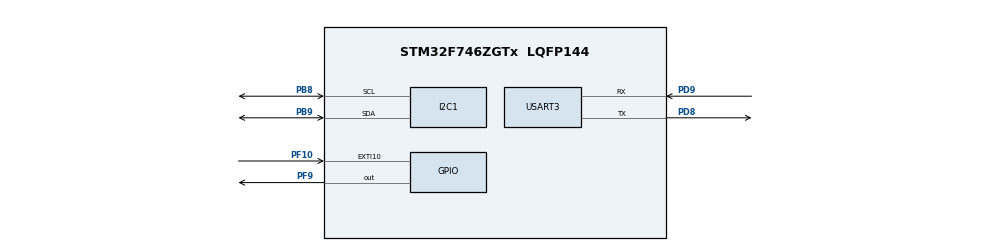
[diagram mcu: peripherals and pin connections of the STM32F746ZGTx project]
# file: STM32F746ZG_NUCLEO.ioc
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Mcu.Family=STM32F7
Mcu.Name=STM32F746ZGTx
Mcu.Package=LQFP144
NVIC.PriorityGroup=NVIC_PRIORITYGROUP_4
PB8.Mode=I2C
PB8.Signal=I2C1_SCL
PB9.Mode=I2C
PB9.Signal=I2C1_SDA
PD8.Mode=Asynchronous
PD8.Signal=USART3_TX
PD9.Mode=Asynchronous
PD9.Signal=USART3_RX
PF10.Signal=GPXTI10
PF9.Signal=GPIO_Output
ProjectManager.HeapSize=0x200
ProjectManager.StackSize=0x400
ProjectManager.TargetToolchain=EWARM V8.32
RCC.HSE_VALUE=25000000
RCC.HSI_VALUE=16000000
RCC.LSE_VALUE=32768
RCC.USBFreq_Value=96000000
RCC.VCOOutputFreq_Value=192000000
STMicroelectronics.I-CUBE-STDIO.1.4.0.STDIN_UART_HANDLER=huart3
STMicroelectronics.I-CUBE-STDIO.1.4.0.STDIOCcCompilerJjIOoOJjSTDIN=USART
STMicroelectronics.I-CUBE-STDIO.1.4.0.STDIOCcCompilerJjIOoOJjSTDOUT=LCD
STMicroelectronics.X-CUBE-COMPONENTS.1.2.3.LCDCcComponentsJjLCDControllerJjGrove=I2C
USART3.VirtualMode-Asynchronous=VM_ASYNC
VP_STMicroelectronics.I-CUBE-STDIO_VS_CompilerJjSTDIO_1.0.0.Mode=CompilerJjSTDIO
VP_STMicroelectronics.X-CUBE-COMPONENTS_VS_ComponentsJjLCD_1.0.0.Mode=ComponentsJjLCD
board=custom

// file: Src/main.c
/* USER CODE BEGIN Header */
/**
  ******************************************************************************
  * @file           : main.c
  * @brief          : Main program body
  ******************************************************************************
  * @attention
  *
  * <h2><center>&copy; Copyright (c) 2020 STMicroelectronics.
  * All rights reserved.</center></h2>
  *
  * This software component is licensed by ST under Ultimate Liberty license
  * SLA0044, the "License"; You may not use this file except in compliance with
  * the License. You may obtain a copy of the License at:
  *                             www.st.com/SLA0044
  *
  ******************************************************************************
  */
/* USER CODE END Header */
#include "main.h"

/* USER CODE BEGIN Includes */
#include <stdio.h>
/* USER CODE END Includes */

I2C_HandleTypeDef hi2c1;

UART_HandleTypeDef huart3;

void SystemClock_Config(void);
static void MX_GPIO_Init(void);
static void MX_I2C1_Init(void);
static void MX_USART3_UART_Init(void);

int main(void)
{

  /* MCU Configuration--------------------------------------------------------*/

  /* Reset of all peripherals, Initializes the Flash interface and the Systick. */
  HAL_Init();

  /* Configure the system clock */
  SystemClock_Config();

  /* Initialize all configured peripherals */
  MX_GPIO_Init();
  MX_I2C1_Init();
  MX_USART3_UART_Init();

  /* Infinite loop */
  /* USER CODE BEGIN WHILE */
  while (1)
  {
#if 0
     char c;
     c = getchar();
     printf("You typed %c\r\n", c);
#else
     static int i = 0;
     printf("Hello World %d\r\n", i);
     i++;
     HAL_Delay(1000);
#endif
    /* USER CODE END WHILE */

  }
}

void SystemClock_Config(void)
{
  RCC_OscInitTypeDef RCC_OscInitStruct = {0};
  RCC_ClkInitTypeDef RCC_ClkInitStruct = {0};
  RCC_PeriphCLKInitTypeDef PeriphClkInitStruct = {0};

  /** Configure the main internal regulator output voltage
  */
  __HAL_RCC_PWR_CLK_ENABLE();
  __HAL_PWR_VOLTAGESCALING_CONFIG(PWR_REGULATOR_VOLTAGE_SCALE3);
  /** Initializes the RCC Oscillators according to the specified parameters
  * in the RCC_OscInitTypeDef structure.
  */
  RCC_OscInitStruct.OscillatorType = RCC_OSCILLATORTYPE_HSI;
  RCC_OscInitStruct.HSIState = RCC_HSI_ON;
  RCC_OscInitStruct.HSICalibrationValue = RCC_HSICALIBRATION_DEFAULT;
  RCC_OscInitStruct.PLL.PLLState = RCC_PLL_NONE;
  if (HAL_RCC_OscConfig(&RCC_OscInitStruct) != HAL_OK)
  {
    Error_Handler();
  }
  /** Initializes the CPU, AHB and APB buses clocks
  */
  RCC_ClkInitStruct.ClockType = RCC_CLOCKTYPE_HCLK|RCC_CLOCKTYPE_SYSCLK
                              |RCC_CLOCKTYPE_PCLK1|RCC_CLOCKTYPE_PCLK2;
  RCC_ClkInitStruct.SYSCLKSource = RCC_SYSCLKSOURCE_HSI;
  RCC_ClkInitStruct.AHBCLKDivider = RCC_SYSCLK_DIV1;
  RCC_ClkInitStruct.APB1CLKDivider = RCC_HCLK_DIV1;
  RCC_ClkInitStruct.APB2CLKDivider = RCC_HCLK_DIV1;

  if (HAL_RCC_ClockConfig(&RCC_ClkInitStruct, FLASH_LATENCY_0) != HAL_OK)
  {
    Error_Handler();
  }
  PeriphClkInitStruct.PeriphClockSelection = RCC_PERIPHCLK_USART3|RCC_PERIPHCLK_I2C1;
  PeriphClkInitStruct.Usart3ClockSelection = RCC_USART3CLKSOURCE_PCLK1;
  PeriphClkInitStruct.I2c1ClockSelection = RCC_I2C1CLKSOURCE_PCLK1;
  if (HAL_RCCEx_PeriphCLKConfig(&PeriphClkInitStruct) != HAL_OK)
  {
    Error_Handler();
  }
}

static void MX_I2C1_Init(void)
{

  hi2c1.Instance = I2C1;
  hi2c1.Init.Timing = 0x00303D5B;
  hi2c1.Init.OwnAddress1 = 0;
  hi2c1.Init.AddressingMode = I2C_ADDRESSINGMODE_7BIT;
  hi2c1.Init.DualAddressMode = I2C_DUALADDRESS_DISABLE;
  hi2c1.Init.OwnAddress2 = 0;
  hi2c1.Init.OwnAddress2Masks = I2C_OA2_NOMASK;
  hi2c1.Init.GeneralCallMode = I2C_GENERALCALL_DISABLE;
  hi2c1.Init.NoStretchMode = I2C_NOSTRETCH_DISABLE;
  if (HAL_I2C_Init(&hi2c1) != HAL_OK)
  {
    Error_Handler();
  }
  /** Configure Analogue filter
  */
  if (HAL_I2CEx_ConfigAnalogFilter(&hi2c1, I2C_ANALOGFILTER_ENABLE) != HAL_OK)
  {
    Error_Handler();
  }
  /** Configure Digital filter
  */
  if (HAL_I2CEx_ConfigDigitalFilter(&hi2c1, 0) != HAL_OK)
  {
    Error_Handler();
  }

}

static void MX_USART3_UART_Init(void)
{

  huart3.Instance = USART3;
  huart3.Init.BaudRate = 115200;
  huart3.Init.WordLength = UART_WORDLENGTH_8B;
  huart3.Init.StopBits = UART_STOPBITS_1;
  huart3.Init.Parity = UART_PARITY_NONE;
  huart3.Init.Mode = UART_MODE_TX_RX;
  huart3.Init.HwFlowCtl = UART_HWCONTROL_NONE;
  huart3.Init.OverSampling = UART_OVERSAMPLING_16;
  huart3.Init.OneBitSampling = UART_ONE_BIT_SAMPLE_DISABLE;
  huart3.AdvancedInit.AdvFeatureInit = UART_ADVFEATURE_NO_INIT;
  if (HAL_UART_Init(&huart3) != HAL_OK)
  {
    Error_Handler();
  }

}

static void MX_GPIO_Init(void)
{
  GPIO_InitTypeDef GPIO_InitStruct = {0};

  /* GPIO Ports Clock Enable */
  __HAL_RCC_GPIOF_CLK_ENABLE();
  __HAL_RCC_GPIOD_CLK_ENABLE();
  __HAL_RCC_GPIOB_CLK_ENABLE();

  /*Configure GPIO pin Output Level */
  HAL_GPIO_WritePin(GPIOF, GPIO_PIN_9, GPIO_PIN_RESET);

  /*Configure GPIO pin : PF9 */
  GPIO_InitStruct.Pin = GPIO_PIN_9;
  GPIO_InitStruct.Mode = GPIO_MODE_OUTPUT_PP;
  GPIO_InitStruct.Pull = GPIO_NOPULL;
  GPIO_InitStruct.Speed = GPIO_SPEED_FREQ_LOW;
  HAL_GPIO_Init(GPIOF, &GPIO_InitStruct);

  /*Configure GPIO pin : PF10 */
  GPIO_InitStruct.Pin = GPIO_PIN_10;
  GPIO_InitStruct.Mode = GPIO_MODE_IT_RISING;
  GPIO_InitStruct.Pull = GPIO_NOPULL;
  HAL_GPIO_Init(GPIOF, &GPIO_InitStruct);

}

void Error_Handler(void)
{
}

/************************ (C) COPYRIGHT STMicroelectronics *****END OF FILE****/
